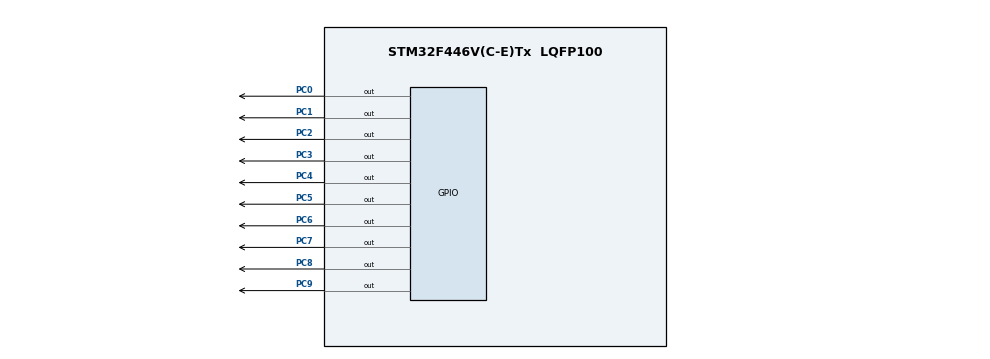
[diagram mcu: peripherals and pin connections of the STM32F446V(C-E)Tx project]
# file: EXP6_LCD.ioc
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Mcu.Family=STM32F4
Mcu.Name=STM32F446V(C-E)Tx
Mcu.Package=LQFP100
NVIC.PriorityGroup=NVIC_PRIORITYGROUP_4
PC0.Signal=GPIO_Output
PC1.Signal=GPIO_Output
PC2.Signal=GPIO_Output
PC3.Signal=GPIO_Output
PC4.Signal=GPIO_Output
PC5.Signal=GPIO_Output
PC6.Signal=GPIO_Output
PC7.Signal=GPIO_Output
PC8.Signal=GPIO_Output
PC9.Signal=GPIO_Output
ProjectManager.HeapSize=0x200
ProjectManager.StackSize=0x400
ProjectManager.TargetToolchain=STM32CubeIDE
RCC.CortexFreq_Value=16000000
RCC.USBFreq_Value=96000000
RCC.VCOOutputFreq_Value=192000000
board=custom

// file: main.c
/* USER CODE BEGIN Header */
/**
  ******************************************************************************
  * @file           : main.c
  * @brief          : Main program body
  ******************************************************************************
  * @attention
  *
  * Copyright (c) 2025 STMicroelectronics.
  * All rights reserved.
  *
  * This software is licensed under terms that can be found in the LICENSE file
  * in the root directory of this software component.
  * If no LICENSE file comes with this software, it is provided AS-IS.
  *
  ******************************************************************************
  */
/* USER CODE END Header */
#include "main.h"
#include "stm32f4xx_hal.h"

void SystemClock_Config(void);
static void MX_GPIO_Init(void);

/* USER CODE BEGIN 0 */
void lcd_enable(void);
void lcd_data(unsigned char);
void lcd_cmd(unsigned char);
void lcd_init(void);
void lcd_clear(void);
void lcd_displayString(int, int, unsigned char*);
/* USER CODE END 0 */

int main(void)
{

  /* USER CODE BEGIN 1 */

	unsigned char str1[] = "PICT";
	unsigned char str2[] = "ESD";

  /* USER CODE END 1 */

  /* MCU Configuration--------------------------------------------------------*/

  /* Reset of all peripherals, Initializes the Flash interface and the Systick. */
  HAL_Init();

  /* Configure the system clock */
  SystemClock_Config();

  /* Initialize all configured peripherals */
  MX_GPIO_Init();

  /* Infinite loop */
  /* USER CODE BEGIN WHILE */

  HAL_Delay(1);
  lcd_init();
  lcd_clear();
  lcd_displayString(1,0,str1);
  lcd_displayString(2,0,str2);
}

void lcd_data(unsigned char data)
{
	//RS = 1 FOR LCD DATA
	GPIOC->BSRR = (1<<8);

	GPIOC->BSRR = (data & 0x01) ? (1<<0) : (uint32_t)(1<<0)<<16;
	GPIOC->BSRR = (data & 0x02) ? (1<<1) : (uint32_t)(1<<1)<<16;
	GPIOC->BSRR = (data & 0x04) ? (1<<2) : (uint32_t)(1<<2)<<16;
	GPIOC->BSRR = (data & 0x08) ? (1<<3) : (uint32_t)(1<<3)<<16;
	GPIOC->BSRR = (data & 0x10) ? (1<<4) : (uint32_t)(1<<4)<<16;
	GPIOC->BSRR = (data & 0x20) ? (1<<5) : (uint32_t)(1<<5)<<16;
	GPIOC->BSRR = (data & 0x40) ? (1<<6) : (uint32_t)(1<<6)<<16;
	GPIOC->BSRR = (data & 0x80) ? (1<<7) : (uint32_t)(1<<7)<<16;

	lcd_enable();
}

void lcd_cmd(unsigned char cmd)
{
	//RS = 0 FOR LCD CMD
	GPIOC->BSRR = (1<<8)<<16;

	GPIOC->BSRR = (cmd & 0x01) ? (1<<0) : (uint32_t)(1<<0)<<16;
	GPIOC->BSRR = (cmd & 0x02) ? (1<<1) : (uint32_t)(1<<1)<<16;
	GPIOC->BSRR = (cmd & 0x04) ? (1<<2) : (uint32_t)(1<<2)<<16;
	GPIOC->BSRR = (cmd & 0x08) ? (1<<3) : (uint32_t)(1<<3)<<16;
	GPIOC->BSRR = (cmd & 0x10) ? (1<<4) : (uint32_t)(1<<4)<<16;
	GPIOC->BSRR = (cmd & 0x20) ? (1<<5) : (uint32_t)(1<<5)<<16;
	GPIOC->BSRR = (cmd & 0x40) ? (1<<6) : (uint32_t)(1<<6)<<16;
	GPIOC->BSRR = (cmd & 0x80) ? (1<<7) : (uint32_t)(1<<7)<<16;

	lcd_enable();
}

void lcd_enable(void)
{
	HAL_Delay(1);
	GPIOC->BSRR = (1<<9);
	HAL_Delay(1);
	GPIOC -> BSRR = (1<<9)<<16;
	HAL_Delay(1);
}

void lcd_init(void)
{
	GPIOC->BSRR = (1<<9)<<16;

	GPIOC->BSRR = ((1<<0)|(1<<1)|(1<<2)|(1<<3)|(1<<4)|(1<<5)|(1<<6)|(1<<7))<<16;

	/* 00111000 = 0x38
	 * 00000110 = 0x06
	 * 00001100 = 0x0C
	 * 00000001  = 0x01
	 * 10000000 = 0x80
	 */
	lcd_cmd(0x38);
	lcd_cmd(0x06);
	lcd_cmd(0x0C);
	lcd_cmd(0x01);
	lcd_cmd(0x80);
}

void lcd_clear(void)
{
	HAL_Delay(1);
	lcd_cmd(0x01);
	HAL_Delay(1);
}

void lcd_displayString(int row, int pos,unsigned char* ch)
{
	unsigned char temp;

	if(row==1)
	{
		temp = 0x80 | (pos);

	}
	else if(row==2)
	{
		temp = 0xC0 |  (pos);
	}

	lcd_cmd(temp);

	while(*ch)
	{
		lcd_data(*ch++);
	}
}

void SystemClock_Config(void)
{
  RCC_OscInitTypeDef RCC_OscInitStruct = {0};
  RCC_ClkInitTypeDef RCC_ClkInitStruct = {0};

  /** Configure the main internal regulator output voltage
  */
  __HAL_RCC_PWR_CLK_ENABLE();
  __HAL_PWR_VOLTAGESCALING_CONFIG(PWR_REGULATOR_VOLTAGE_SCALE3);

  /** Initializes the RCC Oscillators according to the specified parameters
  * in the RCC_OscInitTypeDef structure.
  */
  RCC_OscInitStruct.OscillatorType = RCC_OSCILLATORTYPE_HSI;
  RCC_OscInitStruct.HSIState = RCC_HSI_ON;
  RCC_OscInitStruct.HSICalibrationValue = RCC_HSICALIBRATION_DEFAULT;
  RCC_OscInitStruct.PLL.PLLState = RCC_PLL_NONE;
  if (HAL_RCC_OscConfig(&RCC_OscInitStruct) != HAL_OK)
  {
    Error_Handler();
  }

  /** Initializes the CPU, AHB and APB buses clocks
  */
  RCC_ClkInitStruct.ClockType = RCC_CLOCKTYPE_HCLK|RCC_CLOCKTYPE_SYSCLK
                              |RCC_CLOCKTYPE_PCLK1|RCC_CLOCKTYPE_PCLK2;
  RCC_ClkInitStruct.SYSCLKSource = RCC_SYSCLKSOURCE_HSI;
  RCC_ClkInitStruct.AHBCLKDivider = RCC_SYSCLK_DIV1;
  RCC_ClkInitStruct.APB1CLKDivider = RCC_HCLK_DIV1;
  RCC_ClkInitStruct.APB2CLKDivider = RCC_HCLK_DIV1;

  if (HAL_RCC_ClockConfig(&RCC_ClkInitStruct, FLASH_LATENCY_0) != HAL_OK)
  {
    Error_Handler();
  }
}

static void MX_GPIO_Init(void)
{
  GPIO_InitTypeDef GPIO_InitStruct = {0};

  /* GPIO Ports Clock Enable */
  __HAL_RCC_GPIOC_CLK_ENABLE();

  /*Configure GPIO pin Output Level */
  HAL_GPIO_WritePin(GPIOC, GPIO_PIN_0|GPIO_PIN_1|GPIO_PIN_2|GPIO_PIN_3
                          |GPIO_PIN_4|GPIO_PIN_5|GPIO_PIN_6|GPIO_PIN_7
                          |GPIO_PIN_8|GPIO_PIN_9, GPIO_PIN_RESET);

  /*Configure GPIO pins : PC0 PC1 PC2 PC3
                           PC4 PC5 PC6 PC7
                           PC8 PC9 */
  GPIO_InitStruct.Pin = GPIO_PIN_0|GPIO_PIN_1|GPIO_PIN_2|GPIO_PIN_3
                          |GPIO_PIN_4|GPIO_PIN_5|GPIO_PIN_6|GPIO_PIN_7
                          |GPIO_PIN_8|GPIO_PIN_9;
  GPIO_InitStruct.Mode = GPIO_MODE_OUTPUT_PP;
  GPIO_InitStruct.Pull = GPIO_NOPULL;
  GPIO_InitStruct.Speed = GPIO_SPEED_FREQ_LOW;
  HAL_GPIO_Init(GPIOC, &GPIO_InitStruct);

}

void Error_Handler(void)
{
  __disable_irq();
  while (1)
  {
  }
}
